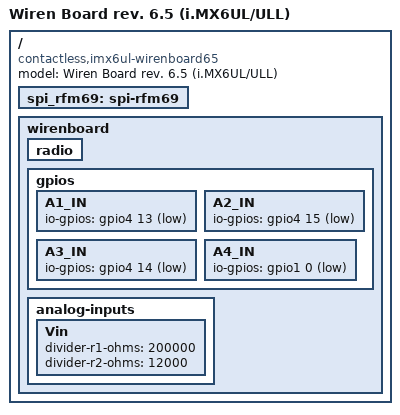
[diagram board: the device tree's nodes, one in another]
/dts-v1/;

#include "imx6ul-wirenboard61.dts"

/* cleanup deprecated radio bindings */
/delete-node/ &spi_rfm69;
/delete-node/ &pinctrl_rfm69_spi_irq; /* pins from radio are using in wb6.7.x */

/ {
	model = "Wiren Board rev. 6.5 (i.MX6UL/ULL)";
	compatible = "contactless,imx6ul-wirenboard65", "contactless,imx6ul-wirenboard61", "contactless,imx6ul-wirenboard60", "contactless,imx6ul-wirenboard-evk", "fsl,imx6ul-14x14-evk", "fsl,imx6ul";

	spi_rfm69: spi-rfm69 {
		/* Wb-dt-overlays's wb6-noradio overlay is looking into spi_rfm69 node.
		Empty node here is to prevent overlay-applying conflicts. */
	};

	wirenboard {

		/* removing deprecated bindings */
		/delete-node/ radio;

		radio {
			/* Wb-dt-overlays's wb6-noradio overlay is looking into radio node.
			Empty node here is to prevent overlay-applying conflicts. */
		};

		gpios {
			A1_IN {
				io-gpios = <&gpio4 13 1>; /* inverted */
			};

			A2_IN {
				io-gpios = <&gpio4 15 1>; /* inverted */
			};

			A3_IN {
				io-gpios = <&gpio4 14 1>; /* inverted */
			};

			A4_IN {
				io-gpios = <&gpio1 0 1>; /* inverted */
			};
		};

		analog-inputs {
			Vin {
				divider-r1-ohms = <200000>;
				divider-r2-ohms = <12000>;
			};
		};
    };
};
